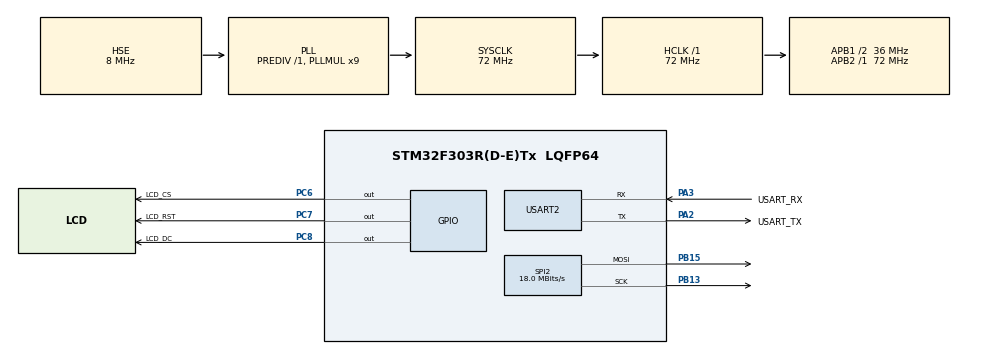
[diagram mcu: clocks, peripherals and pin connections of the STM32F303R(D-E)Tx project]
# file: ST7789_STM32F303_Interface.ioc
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Dma.Request0=SPI2_TX
Dma.SPI2_TX.0.Direction=DMA_MEMORY_TO_PERIPH
Dma.SPI2_TX.0.Instance=DMA1_Channel5
Dma.SPI2_TX.0.MemDataAlignment=DMA_MDATAALIGN_HALFWORD
Dma.SPI2_TX.0.MemInc=DMA_MINC_ENABLE
Dma.SPI2_TX.0.Mode=DMA_NORMAL
Dma.SPI2_TX.0.PeriphDataAlignment=DMA_PDATAALIGN_HALFWORD
Dma.SPI2_TX.0.PeriphInc=DMA_PINC_DISABLE
Dma.SPI2_TX.0.Priority=DMA_PRIORITY_LOW
Mcu.Family=STM32F3
Mcu.Name=STM32F303R(D-E)Tx
Mcu.Package=LQFP64
NVIC.DMA1_Channel5_IRQn=true\:0\:0\:false\:false\:true\:false\:true\:true
NVIC.PriorityGroup=NVIC_PRIORITYGROUP_0
PA13.GPIO_Label=TMS
PA13.Mode=Serial_Wire
PA13.Signal=SYS_JTMS-SWDIO
PA14.GPIO_Label=TCK
PA14.Mode=Serial_Wire
PA14.Signal=SYS_JTCK-SWCLK
PA2.GPIO_Label=USART_TX
PA2.GPIO_Mode=GPIO_MODE_AF_PP
PA2.GPIO_PuPd=GPIO_NOPULL
PA2.GPIO_Speed=GPIO_SPEED_FREQ_LOW
PA2.Mode=Asynchronous
PA2.Signal=USART2_TX
PA3.GPIO_Label=USART_RX
PA3.GPIO_Mode=GPIO_MODE_AF_PP
PA3.GPIO_PuPd=GPIO_NOPULL
PA3.GPIO_Speed=GPIO_SPEED_FREQ_LOW
PA3.Mode=Asynchronous
PA3.Signal=USART2_RX
PB13.Mode=TX_Only_Simplex_Unidirect_Master
PB13.Signal=SPI2_SCK
PB15.Mode=TX_Only_Simplex_Unidirect_Master
PB15.Signal=SPI2_MOSI
PB3.GPIO_Label=SWO
PB3.Signal=SYS_JTDO-TRACESWO
PC14-OSC32_IN.Mode=LSE-External-Oscillator
PC14-OSC32_IN.Signal=RCC_OSC32_IN
PC15-OSC32_OUT.Mode=LSE-External-Oscillator
PC15-OSC32_OUT.Signal=RCC_OSC32_OUT
PC6.GPIO_Label=LCD_CS
PC6.GPIO_PuPd=GPIO_PULLUP
PC6.GPIO_Speed=GPIO_SPEED_FREQ_HIGH
PC6.PinState=GPIO_PIN_SET
PC6.Signal=GPIO_Output
PC7.GPIO_Label=LCD_RST
PC7.GPIO_PuPd=GPIO_PULLUP
PC7.GPIO_Speed=GPIO_SPEED_FREQ_HIGH
PC7.PinState=GPIO_PIN_SET
PC7.Signal=GPIO_Output
PC8.GPIO_Label=LCD_DC
PC8.GPIO_PuPd=GPIO_PULLUP
PC8.GPIO_Speed=GPIO_SPEED_FREQ_HIGH
PC8.PinState=GPIO_PIN_SET
PC8.Signal=GPIO_Output
PF0-OSC_IN.Mode=HSE-External-Clock-Source
PF0-OSC_IN.Signal=RCC_OSC_IN
PF1-OSC_OUT.Signal=RCC_OSC_OUT
ProjectManager.HeapSize=0x200
ProjectManager.StackSize=0x400
ProjectManager.TargetToolchain=STM32CubeIDE
RCC.AHBFreq_Value=72000000
RCC.APB1CLKDivider=RCC_HCLK_DIV2
RCC.APB1Freq_Value=36000000
RCC.APB1TimFreq_Value=72000000
RCC.APB2Freq_Value=72000000
RCC.APB2TimFreq_Value=72000000
RCC.CortexFreq_Value=72000000
RCC.HCLKFreq_Value=72000000
RCC.HSE_VALUE=8000000
RCC.HSI_VALUE=8000000
RCC.PLLM=8
RCC.PLLMUL=RCC_PLL_MUL9
RCC.PLLN=336
RCC.PLLP=RCC_PLLP_DIV4
RCC.PLLQ=7
RCC.PLLSourceVirtual=RCC_PLLSOURCE_HSE
RCC.RCC_PLLsource_Clock_Source_FROM_HSE=RCC_HSE_PREDIV_DIV2
RCC.SYSCLKFreq_VALUE=72000000
RCC.SYSCLKSourceVirtual=RCC_SYSCLKSOURCE_PLLCLK
RCC.USBFreq_Value=72000000
SPI2.CLKPhase=SPI_PHASE_2EDGE
SPI2.CLKPolarity=SPI_POLARITY_HIGH
SPI2.CalculateBaudRate=18.0 MBits/s
SPI2.DataSize=SPI_DATASIZE_8BIT
SPI2.Direction=SPI_DIRECTION_2LINES
SPI2.Mode=SPI_MODE_MASTER
SPI2.VirtualType=VM_MASTER
USART2.VirtualMode-Asynchronous=VM_ASYNC
board=NUCLEO-F303RE

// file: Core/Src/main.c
/* USER CODE BEGIN Header */
/**
  ******************************************************************************
  * @file           : main.c
  * @brief          : Main program body
  ******************************************************************************
  * @attention
  *
  * Copyright (c) 2026 STMicroelectronics.
  * All rights reserved.
  *
  * This software is licensed under terms that can be found in the LICENSE file
  * in the root directory of this software component.
  * If no LICENSE file comes with this software, it is provided AS-IS.
  *
  ******************************************************************************
  */
/* USER CODE END Header */
#include "main.h"

/* USER CODE BEGIN Includes */
#include "lcd.h"
/* USER CODE END Includes */

SPI_HandleTypeDef hspi2;
DMA_HandleTypeDef hdma_spi2_tx;

UART_HandleTypeDef huart2;

void SystemClock_Config(void);
static void MX_GPIO_Init(void);
static void MX_DMA_Init(void);
static void MX_SPI2_Init(void);
static void MX_USART2_UART_Init(void);

int main(void)
{

  /* MCU Configuration--------------------------------------------------------*/

  /* Reset of all peripherals, Initializes the Flash interface and the Systick. */
  HAL_Init();

  /* Configure the system clock */
  SystemClock_Config();

  /* Initialize all configured peripherals */
  MX_GPIO_Init();
  MX_DMA_Init();
  MX_SPI2_Init();
  MX_USART2_UART_Init();
  /* USER CODE BEGIN 2 */
  HAL_Delay(150);
  LCD_init();                                         // Initialize TFT [35, 41]
  HAL_Delay(150);
  LCD_InvertColors(0);
  //LCD_SetRotation(3);                                // 320px Landscape mode [42, 43]

  UG_FillScreen(C_SALMON);
  HAL_Delay(1500);
  UG_FillScreen(C_YELLOW);
  HAL_Delay(3000);

  LCD_Test();
  /* USER CODE END 2 */

  /* Infinite loop */
  while (1)
  {

  }
}

void SystemClock_Config(void)
{
  RCC_OscInitTypeDef RCC_OscInitStruct = {0};
  RCC_ClkInitTypeDef RCC_ClkInitStruct = {0};
  RCC_PeriphCLKInitTypeDef PeriphClkInit = {0};

  /** Initializes the RCC Oscillators according to the specified parameters
  * in the RCC_OscInitTypeDef structure.
  */
  RCC_OscInitStruct.OscillatorType = RCC_OSCILLATORTYPE_HSE;
  RCC_OscInitStruct.HSEState = RCC_HSE_BYPASS;
  RCC_OscInitStruct.HSIState = RCC_HSI_ON;
  RCC_OscInitStruct.PLL.PLLState = RCC_PLL_ON;
  RCC_OscInitStruct.PLL.PLLSource = RCC_PLLSOURCE_HSE;
  RCC_OscInitStruct.PLL.PLLMUL = RCC_PLL_MUL9;
  RCC_OscInitStruct.PLL.PREDIV = RCC_PREDIV_DIV1;
  if (HAL_RCC_OscConfig(&RCC_OscInitStruct) != HAL_OK)
  {
    Error_Handler();
  }

  /** Initializes the CPU, AHB and APB buses clocks
  */
  RCC_ClkInitStruct.ClockType = RCC_CLOCKTYPE_HCLK|RCC_CLOCKTYPE_SYSCLK
                              |RCC_CLOCKTYPE_PCLK1|RCC_CLOCKTYPE_PCLK2;
  RCC_ClkInitStruct.SYSCLKSource = RCC_SYSCLKSOURCE_PLLCLK;
  RCC_ClkInitStruct.AHBCLKDivider = RCC_SYSCLK_DIV1;
  RCC_ClkInitStruct.APB1CLKDivider = RCC_HCLK_DIV2;
  RCC_ClkInitStruct.APB2CLKDivider = RCC_HCLK_DIV1;

  if (HAL_RCC_ClockConfig(&RCC_ClkInitStruct, FLASH_LATENCY_2) != HAL_OK)
  {
    Error_Handler();
  }
  PeriphClkInit.PeriphClockSelection = RCC_PERIPHCLK_USART2;
  PeriphClkInit.Usart2ClockSelection = RCC_USART2CLKSOURCE_PCLK1;
  if (HAL_RCCEx_PeriphCLKConfig(&PeriphClkInit) != HAL_OK)
  {
    Error_Handler();
  }
}

static void MX_SPI2_Init(void)
{

  /* SPI2 parameter configuration*/
  hspi2.Instance = SPI2;
  hspi2.Init.Mode = SPI_MODE_MASTER;
  hspi2.Init.Direction = SPI_DIRECTION_2LINES;
  hspi2.Init.DataSize = SPI_DATASIZE_8BIT;
  hspi2.Init.CLKPolarity = SPI_POLARITY_HIGH;
  hspi2.Init.CLKPhase = SPI_PHASE_2EDGE;
  hspi2.Init.NSS = SPI_NSS_SOFT;
  hspi2.Init.BaudRatePrescaler = SPI_BAUDRATEPRESCALER_2;
  hspi2.Init.FirstBit = SPI_FIRSTBIT_MSB;
  hspi2.Init.TIMode = SPI_TIMODE_DISABLE;
  hspi2.Init.CRCCalculation = SPI_CRCCALCULATION_DISABLE;
  hspi2.Init.CRCPolynomial = 7;
  hspi2.Init.CRCLength = SPI_CRC_LENGTH_DATASIZE;
  hspi2.Init.NSSPMode = SPI_NSS_PULSE_DISABLE;
  if (HAL_SPI_Init(&hspi2) != HAL_OK)
  {
    Error_Handler();
  }

}

static void MX_USART2_UART_Init(void)
{

  huart2.Instance = USART2;
  huart2.Init.BaudRate = 38400;
  huart2.Init.WordLength = UART_WORDLENGTH_8B;
  huart2.Init.StopBits = UART_STOPBITS_1;
  huart2.Init.Parity = UART_PARITY_NONE;
  huart2.Init.Mode = UART_MODE_TX_RX;
  huart2.Init.HwFlowCtl = UART_HWCONTROL_NONE;
  huart2.Init.OverSampling = UART_OVERSAMPLING_16;
  huart2.Init.OneBitSampling = UART_ONE_BIT_SAMPLE_DISABLE;
  huart2.AdvancedInit.AdvFeatureInit = UART_ADVFEATURE_NO_INIT;
  if (HAL_UART_Init(&huart2) != HAL_OK)
  {
    Error_Handler();
  }

}

static void MX_DMA_Init(void)
{

  /* DMA controller clock enable */
  __HAL_RCC_DMA1_CLK_ENABLE();

  /* DMA interrupt init */
  /* DMA1_Channel5_IRQn interrupt configuration */
  HAL_NVIC_SetPriority(DMA1_Channel5_IRQn, 0, 0);
  HAL_NVIC_EnableIRQ(DMA1_Channel5_IRQn);

}

static void MX_GPIO_Init(void)
{
  GPIO_InitTypeDef GPIO_InitStruct = {0};

  /* GPIO Ports Clock Enable */
  __HAL_RCC_GPIOC_CLK_ENABLE();
  __HAL_RCC_GPIOF_CLK_ENABLE();
  __HAL_RCC_GPIOA_CLK_ENABLE();
  __HAL_RCC_GPIOB_CLK_ENABLE();

  /*Configure GPIO pin Output Level */
  HAL_GPIO_WritePin(GPIOC, LCD_CS_Pin|LCD_RST_Pin|LCD_DC_Pin, GPIO_PIN_SET);

  /*Configure GPIO pins : LCD_CS_Pin LCD_RST_Pin LCD_DC_Pin */
  GPIO_InitStruct.Pin = LCD_CS_Pin|LCD_RST_Pin|LCD_DC_Pin;
  GPIO_InitStruct.Mode = GPIO_MODE_OUTPUT_PP;
  GPIO_InitStruct.Pull = GPIO_PULLUP;
  GPIO_InitStruct.Speed = GPIO_SPEED_FREQ_HIGH;
  HAL_GPIO_Init(GPIOC, &GPIO_InitStruct);

}

void Error_Handler(void)
{
  __disable_irq();
  while (1)
  {
  }
}
